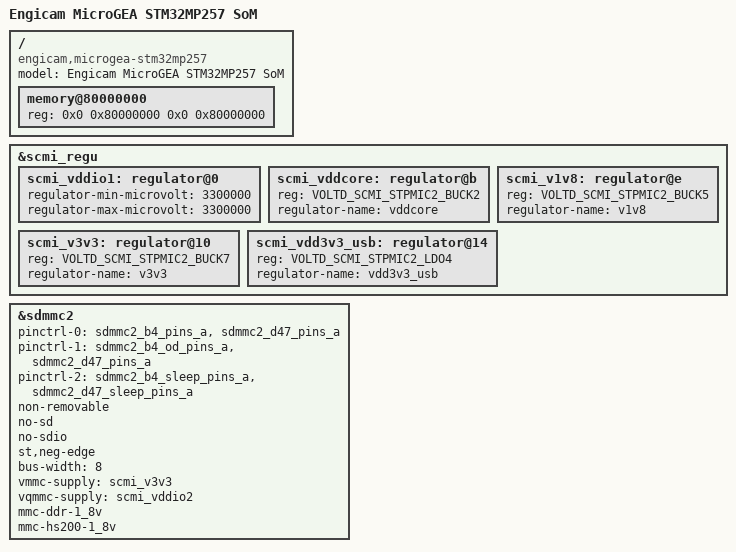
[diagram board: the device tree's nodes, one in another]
// SPDX-License-Identifier: GPL-2.0
/*
 * Copyright (C) 2026 Amarula Solutions, Dario Binacchi <dario.binacchi@amarulasolutions.com>
 * Copyright (C) 2026 Engicam srl
 */

/dts-v1/;

#include <dt-bindings/regulator/st,stm32mp25-regulator.h>
#include "stm32mp257.dtsi"
#include "stm32mp25-pinctrl.dtsi"
#include "stm32mp25xxai-pinctrl.dtsi"

/ {
	model = "Engicam MicroGEA STM32MP257 SoM";
	compatible = "engicam,microgea-stm32mp257", "st,stm32mp257";

	memory@80000000 {
		device_type = "memory";
		reg = <0x0 0x80000000 0x0 0x80000000>;
	};
};

&scmi_regu {
	scmi_vddio1: regulator@0 {
		regulator-min-microvolt = <3300000>;
		regulator-max-microvolt = <3300000>;
	};
	scmi_vddcore: regulator@b {
		reg = <VOLTD_SCMI_STPMIC2_BUCK2>;
		regulator-name = "vddcore";
	};
	scmi_v1v8: regulator@e {
		reg = <VOLTD_SCMI_STPMIC2_BUCK5>;
		regulator-name = "v1v8";
	};
	scmi_v3v3: regulator@10 {
		reg = <VOLTD_SCMI_STPMIC2_BUCK7>;
		regulator-name = "v3v3";
	};
	scmi_vdd3v3_usb: regulator@14 {
		reg = <VOLTD_SCMI_STPMIC2_LDO4>;
		regulator-name = "vdd3v3_usb";
	};
};

/* eMMC */
&sdmmc2 {
	pinctrl-names = "default", "opendrain", "sleep";
	pinctrl-0 = <&sdmmc2_b4_pins_a &sdmmc2_d47_pins_a>;
	pinctrl-1 = <&sdmmc2_b4_od_pins_a &sdmmc2_d47_pins_a>;
	pinctrl-2 = <&sdmmc2_b4_sleep_pins_a &sdmmc2_d47_sleep_pins_a>;
	non-removable;
	no-sd;
	no-sdio;
	st,neg-edge;
	bus-width = <8>;
	vmmc-supply = <&scmi_v3v3>;
	vqmmc-supply = <&scmi_vddio2>;
	mmc-ddr-1_8v;
	mmc-hs200-1_8v;
	status = "okay";
};
